AUTOSAR XML (schema 4-2-2)
package /ComponentTypes
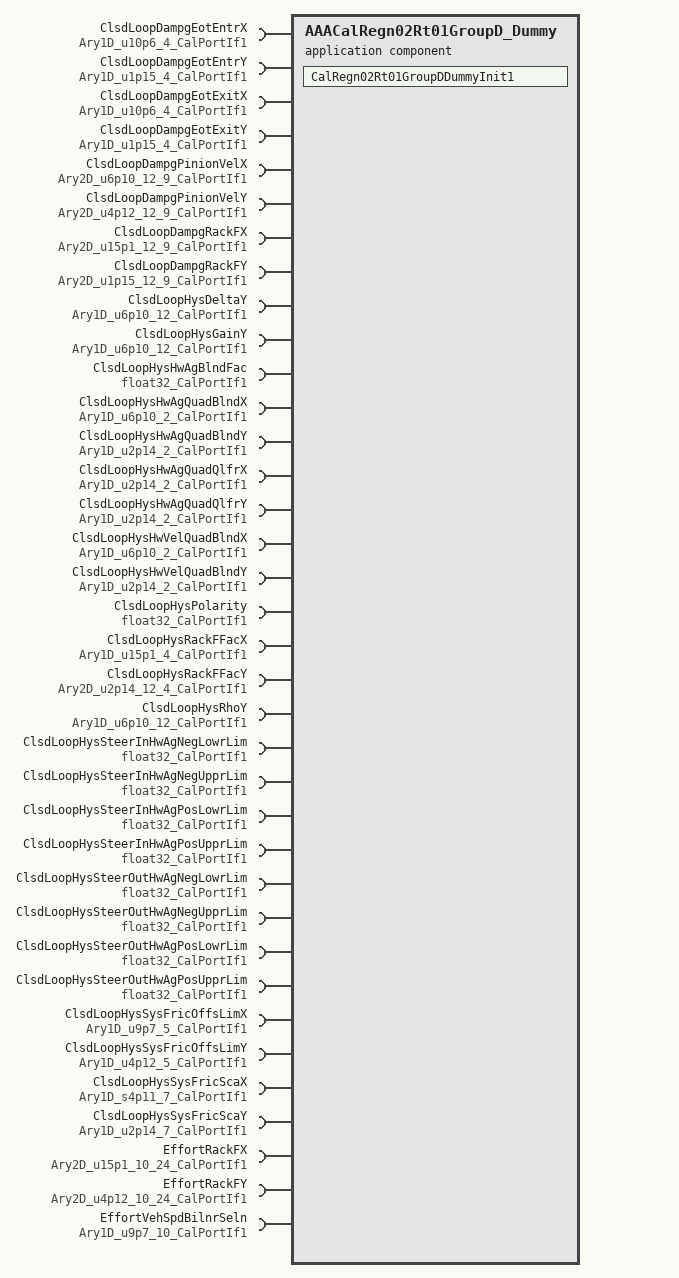
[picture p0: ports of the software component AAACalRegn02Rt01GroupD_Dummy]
  application sw component type AAACalRegn02Rt01GroupD_Dummy
    36 x require port:
      ClsdLoopDampgEotEntrX: parameter-require-com-spec{init-value=[0, 448, 3008, 3520], parameter=Ary1D}, required-interface=Ary1D_u10p6_4_CalPortIf1
      ClsdLoopDampgEotEntrY: parameter-require-com-spec{init-value=[557, 557, 0, 0], parameter=Ary1D}, required-interface=Ary1D_u1p15_4_CalPortIf1
      ClsdLoopDampgEotExitX: parameter-require-com-spec{init-value=[0, 448, 3008, 3520], parameter=Ary1D}, required-interface=Ary1D_u10p6_4_CalPortIf1
      ClsdLoopDampgEotExitY: parameter-require-com-spec{init-value=[557, 557, 0, 0], parameter=Ary1D}, required-interface=Ary1D_u1p15_4_CalPortIf1
      ClsdLoopDampgPinionVelX: parameter-require-com-spec{init-value=12 x [0, 89, 179, 357, 715, 1430, 2860, 5719, 8936], parameter=Ary2D}, required-interface=Ary2D_u6p10_12_9_CalPortIf1
      ClsdLoopDampgPinionVelY: parameter-require-com-spec{init-value=12 x [0, 64, 124, 288, 900, 2456, 5980, 12288, 12288], parameter=Ary2D}, required-interface=Ary2D_u4p12_12_9_CalPortIf1
      ClsdLoopDampgRackFX: parameter-require-com-spec{init-value=12 x [0, 394, 798, 1204, 1610, 2009, 2406, 2834, 29568], parameter=Ary2D}, required-interface=Ary2D_u15p1_12_9_CalPortIf1
      ClsdLoopDampgRackFY: parameter-require-com-spec{init-value=12 x 9 x 32768, parameter=Ary2D}, required-interface=Ary2D_u1p15_12_9_CalPortIf1
      ClsdLoopHysDeltaY: parameter-require-com-spec{init-value=[205, 205, 256, 307, 512, 512, 512, 512, 512, 512, 512, 512], parameter=Ary1D}, required-interface=Ary1D_u6p10_12_CalPortIf1
      ClsdLoopHysGainY: parameter-require-com-spec{init-value=[205, 205, 205, 102, 102, 51, 51, 51, 51, 51, 51, 51], parameter=Ary1D}, required-interface=Ary1D_u6p10_12_CalPortIf1
      ClsdLoopHysHwAgBlndFac: parameter-require-com-spec{init-value=0.2, parameter=Val}, required-interface=float32_CalPortIf1
      ClsdLoopHysHwAgQuadBlndX: parameter-require-com-spec{init-value=[0, 102], parameter=Ary1D}, required-interface=Ary1D_u6p10_2_CalPortIf1
      ClsdLoopHysHwAgQuadBlndY: parameter-require-com-spec{init-value=[0, 16384], parameter=Ary1D}, required-interface=Ary1D_u2p14_2_CalPortIf1
      ClsdLoopHysHwAgQuadQlfrX: parameter-require-com-spec{init-value=[0, 16384], parameter=Ary1D}, required-interface=Ary1D_u2p14_2_CalPortIf1
      ClsdLoopHysHwAgQuadQlfrY: parameter-require-com-spec{init-value=[0, 16384], parameter=Ary1D}, required-interface=Ary1D_u2p14_2_CalPortIf1
      ClsdLoopHysHwVelQuadBlndX: parameter-require-com-spec{init-value=[0, 1024], parameter=Ary1D}, required-interface=Ary1D_u6p10_2_CalPortIf1
      ClsdLoopHysHwVelQuadBlndY: parameter-require-com-spec{init-value=[0, 16384], parameter=Ary1D}, required-interface=Ary1D_u2p14_2_CalPortIf1
      ClsdLoopHysPolarity: parameter-require-com-spec{init-value=1, parameter=Val}, required-interface=float32_CalPortIf1
      ClsdLoopHysRackFFacX: parameter-require-com-spec{init-value=[0, 2000, 10000, 18000], parameter=Ary1D}, required-interface=Ary1D_u15p1_4_CalPortIf1
      ClsdLoopHysRackFFacY: parameter-require-com-spec{init-value=12 x [164, 164, 164, 164], parameter=Ary2D}, required-interface=Ary2D_u2p14_12_4_CalPortIf1
      ClsdLoopHysRhoY: parameter-require-com-spec{init-value=[10240, 10240, 5120, 5120, 3072, 3072, 2560, 2560, 2560, 2560, 2560, 0], parameter=Ary1D}, required-interface=Ary1D_u6p10_12_CalPortIf1
      ClsdLoopHysSteerInHwAgNegLowrLim: parameter-require-com-spec{init-value=-1, parameter=Val}, required-interface=float32_CalPortIf1
      ClsdLoopHysSteerInHwAgNegUpprLim: parameter-require-com-spec{init-value=1, parameter=Val}, required-interface=float32_CalPortIf1
      ClsdLoopHysSteerInHwAgPosLowrLim: parameter-require-com-spec{init-value=-1, parameter=Val}, required-interface=float32_CalPortIf1
      ClsdLoopHysSteerInHwAgPosUpprLim: parameter-require-com-spec{init-value=1, parameter=Val}, required-interface=float32_CalPortIf1
      ClsdLoopHysSteerOutHwAgNegLowrLim: parameter-require-com-spec{init-value=-0.1, parameter=Val}, required-interface=float32_CalPortIf1
      ClsdLoopHysSteerOutHwAgNegUpprLim: parameter-require-com-spec{init-value=0.1, parameter=Val}, required-interface=float32_CalPortIf1
      ClsdLoopHysSteerOutHwAgPosLowrLim: parameter-require-com-spec{init-value=-0.1, parameter=Val}, required-interface=float32_CalPortIf1
      ClsdLoopHysSteerOutHwAgPosUpprLim: parameter-require-com-spec{init-value=0.1, parameter=Val}, required-interface=float32_CalPortIf1
      ClsdLoopHysSysFricOffsLimX: parameter-require-com-spec{init-value=[0, 1280, 5120, 10240, 25600], parameter=Ary1D}, required-interface=Ary1D_u9p7_5_CalPortIf1
      ClsdLoopHysSysFricOffsLimY: parameter-require-com-spec{init-value=[20480, 20480, 16384, 4096, 0], parameter=Ary1D}, required-interface=Ary1D_u4p12_5_CalPortIf1
      ClsdLoopHysSysFricScaX: parameter-require-com-spec{init-value=[-10240, -8192, -4096, 0, 4096, 8192, 10240], parameter=Ary1D}, required-interface=Ary1D_s4p11_7_CalPortIf1
      ClsdLoopHysSysFricScaY: parameter-require-com-spec{init-value=[19661, 19661, 18022, 16384, 14746, 13107, 13107], parameter=Ary1D}, required-interface=Ary1D_u2p14_7_CalPortIf1
      EffortRackFX: parameter-require-com-spec{init-value=[[0, 123, 258, 395, 530, 661, 798, 934, 1069, 1204, 1335, 1474, 1610, 1741, 1874, 2009, 2145, 2280, 2406, 2540, 2675, 2834, 2957, 29568], [0, 124, 258, 394, 528, 664, 798, 932, 1066, 1201, 1340, 1472, 1609, 1744, 1876, 2014, 2145, 2277, 2425, 2543, 2692, 2834, 2957, 29568], [0, 124, 258, 393, 527, 663, 798, 934, 1067, 1203, 1339, 1471, 1608, 1739, 1878, 2009, 2145, 2288, 2421, 2546, 2676, 2834, 2957, 29568], [0, 124, 259, 392, 529, 664, 798, 934, 1068, 1202, 1336, 1472, 1609, 1743, 1880, 2009, 2145, 2277, 2413, 2548, 2695, 2815, 2957, 29568], [0, 122, 258, 392, 529, 662, 798, 932, 1068, 1201, 1339, 1474, 1607, 1742, 1880, 2013, 2145, 2285, 2418, 2549, 2691, 2834, 2957, 29568], [0, 123, 257, 392, 527, 664, 798, 934, 1069, 1204, 1337, 1472, 1605, 1741, 1881, 2009, 2145, 2280, 2422, 2549, 2686, 2826, 2957, 29568], [0, 124, 259, 394, 528, 663, 798, 932, 1069, 1203, 1336, 1475, 1608, 1740, 1874, 2013, 2145, 2287, 2411, 2550, 2682, 2816, 2957, 29568], [0, 123, 258, 394, 528, 662, 798, 934, 1066, 1203, 1338, 1473, 1606, 1744, 1875, 2009, 2145, 2282, 2415, 2551, 2678, 2834, 2957, 29568], [0, 124, 259, 394, 529, 663, 798, 932, 1067, 1202, 1337, 1471, 1609, 1743, 1876, 2012, 2145, 2278, 2419, 2551, 2698, 2826, 2957, 29568], [0, 122, 258, 394, 527, 662, 798, 934, 1067, 1202, 1339, 1473, 1607, 1742, 1876, 2009, 2145, 2284, 2423, 2552, 2694, 2817, 2957, 29568]], parameter=Ary2D}, required-interface=Ary2D_u15p1_10_24_CalPortIf1
      EffortRackFY: parameter-require-com-spec{init-value=[[0, 512, 1072, 1632, 2176, 2688, 3200, 3680, 4128, 4544, 4912, 5264, 5568, 5824, 6048, 6240, 6400, 6528, 6624, 6704, 6768, 6832, 6864, 15712], [0, 592, 1232, 1872, 2496, 3104, 3680, 4224, 4736, 5216, 5664, 6048, 6400, 6704, 6960, 7184, 7360, 7504, 7632, 7712, 7792, 7856, 7904, 18080], [0, 672, 1392, 2112, 2816, 3504, 4160, 4784, 5360, 5904, 6400, 6832, 7232, 7568, 7872, 8112, 8320, 8496, 8624, 8720, 8800, 8880, 8928, 20432], [0, 720, 1504, 2272, 3040, 3776, 4480, 5152, 5776, 6352, 6880, 7360, 7792, 8160, 8480, 8736, 8960, 9136, 9280, 9392, 9488, 9552, 9616, 22000], [0, 736, 1552, 2352, 3152, 3904, 4640, 5328, 5984, 6576, 7136, 7632, 8064, 8448, 8784, 9056, 9280, 9472, 9616, 9728, 9824, 9904, 9968, 22784], [0, 768, 1600, 2432, 3248, 4048, 4800, 5520, 6192, 6816, 7376, 7888, 8336, 8736, 9088, 9360, 9600, 9792, 9952, 10064, 10160, 10240, 10304, 23584], [0, 800, 1664, 2528, 3360, 4176, 4960, 5696, 6400, 7040, 7616, 8160, 8624, 9024, 9376, 9680, 9920, 10128, 10272, 10400, 10496, 10576, 10656, 24368], [0, 816, 1712, 2608, 3472, 4304, 5120, 5888, 6592, 7264, 7872, 8416, 8896, 9328, 9680, 9984, 10240, 10448, 10608, 10736, 10832, 10928, 10992, 25152], [0, 848, 1776, 2688, 3584, 4448, 5280, 6064, 6800, 7488, 8112, 8672, 9184, 9616, 9984, 10304, 10560, 10768, 10944, 11072, 11184, 11264, 11344, 25936], [0, 864, 1824, 2768, 3680, 4576, 5440, 6256, 7008, 7712, 8368, 8944, 9456, 9904, 10288, 10608, 10880, 11104, 11280, 11408, 11520, 11600, 11680, 26720]], parameter=Ary2D}, required-interface=Ary2D_u4p12_10_24_CalPortIf1
      EffortVehSpdBilnrSeln: parameter-require-com-spec{init-value=[0, 1920, 3840, 7680, 10240, 12800, 15360, 19200, 23040, 28160], parameter=Ary1D}, required-interface=Ary1D_u9p7_10_CalPortIf1
    behavior AAACalRegn02Rt01GroupD_Dummy_InternalBehavior: supports-multiple-instantiation=true
      init event AAACalRegn02Rt01GroupD_Dummy_InitEvent: start-on-event=CalRegn02Rt01GroupDDummyInit1
      runnable CalRegn02Rt01GroupDDummyInit1
  swc implementation AAACalRegn02Rt00GroupD_Dummy_Implementation: behavior=AAACalRegn02Rt01GroupD_Dummy_InternalBehavior
    code-descriptors:
      code Default: artifact-descriptors=autosar-engineering-object={short-label=Default, category=SWSRC}
